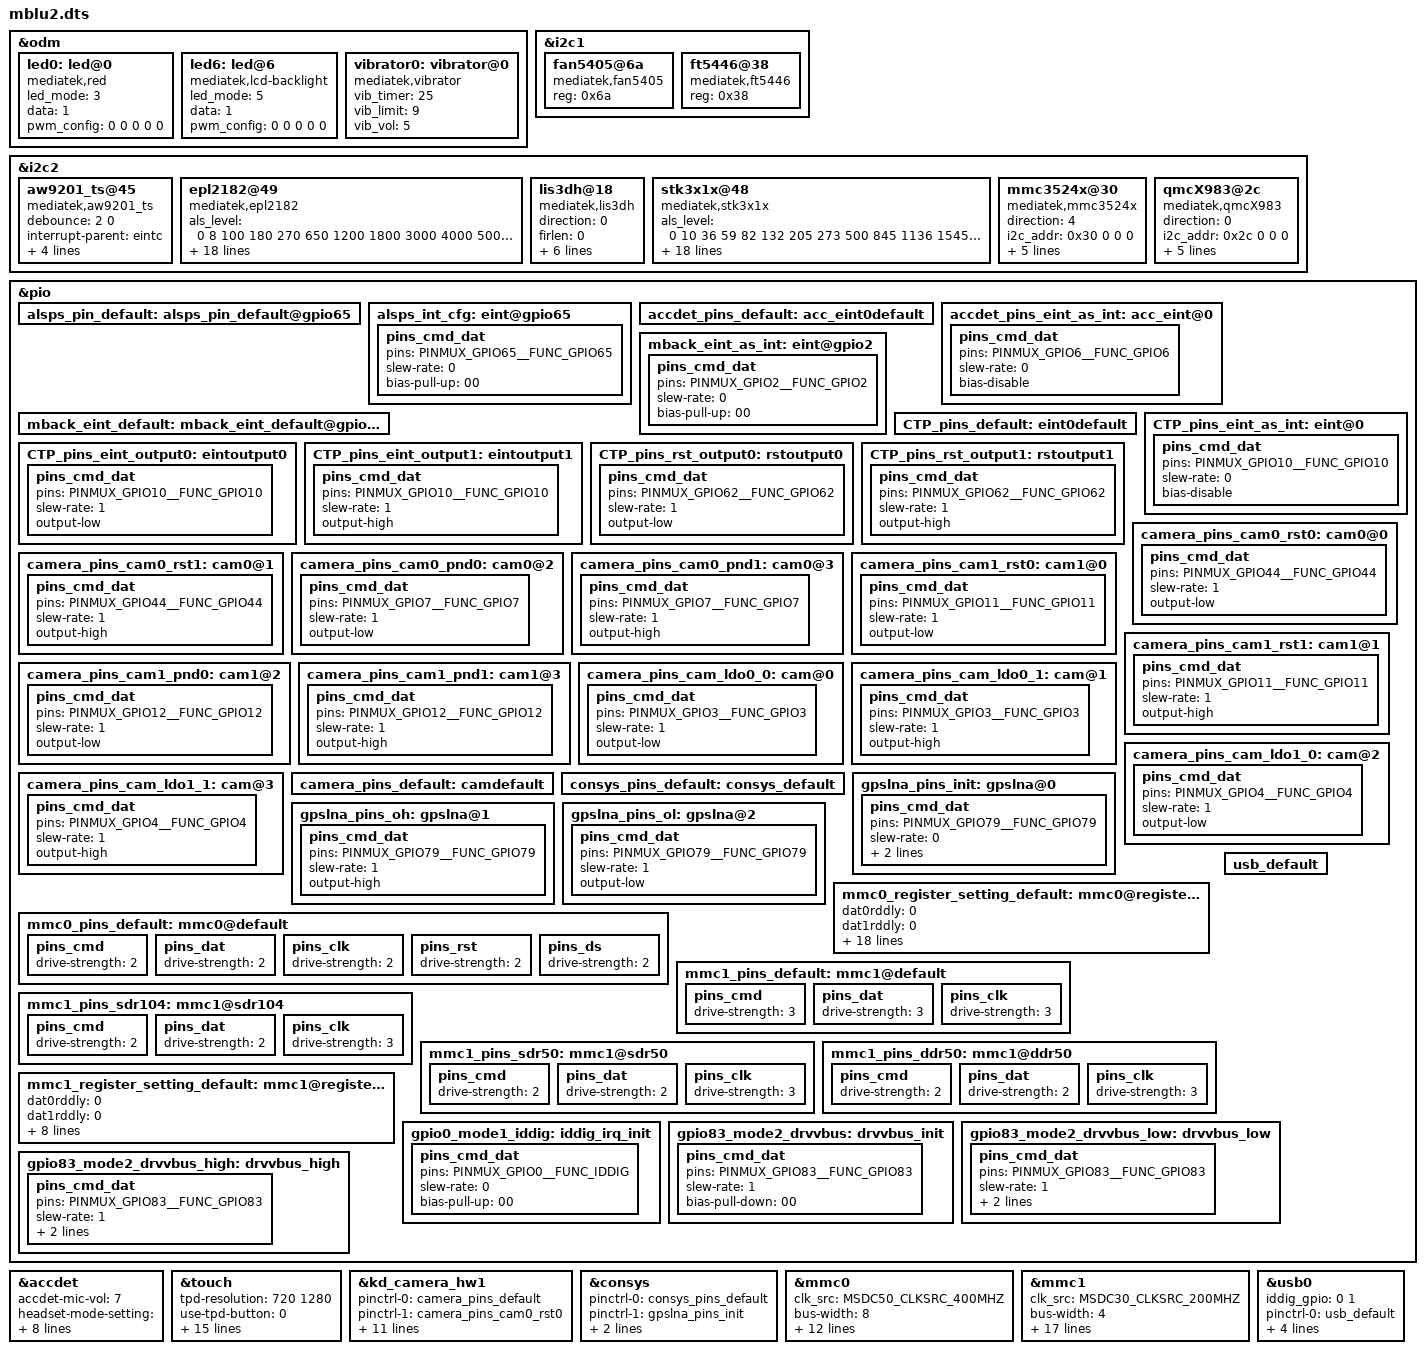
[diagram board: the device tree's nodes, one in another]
#include <generated/autoconf.h>
/dts-v1/;

#include "mt6735.dts"

&odm {
	led0:led@0 {
		compatible = "mediatek,red";
		led_mode = <3>;
		data = <1>;
		pwm_config = <0 0 0 0 0>;
	};

	led6:led@6 {
		compatible = "mediatek,lcd-backlight";
		led_mode = <5>;
		data = <1>;
		pwm_config = <0 0 0 0 0>;
	};

	vibrator0:vibrator@0 {
		compatible = "mediatek,vibrator";
		vib_timer = <25>;
		vib_limit = <9>;
		vib_vol= <5>;
	};
};

&i2c1 {
	fan5405@6a {
		compatible = "mediatek,fan5405";
		reg = <0x6a>;
	};

	ft5446@38 {
		compatible = "mediatek,ft5446";
		reg = <0x38>;
	};
};

&i2c2 {
	aw9201_ts@45 {
		compatible = "mediatek,aw9201_ts";
		debounce = <2 0>;
		interrupt-parent = <&eintc>;
		interrupts = <2 IRQ_TYPE_LEVEL_LOW>;
		pinctrl-0 = <&mback_eint_default>;
		pinctrl-1 = <&mback_eint_as_int>;
		pinctrl-names = "mback_eint_default", "mback_eint_as_int";
		reg = <0x45>;
	};

	epl2182@49 {
		als_level = <0 8 100 180 270 650 1200 1800 3000 4000 5000 7000 9000 15000 20000>;
		als_value = <0 0 150 340 430 570 700 800 950 1500 3000 5000 7000 9000 10240 10240>;
		compatible = "mediatek,epl2182";
		debounce = <65 0>;
		i2c_addr = <0x49 0 0 0>;
		i2c_num = <2>;
		interrupt-parent = <&eintc>;
		interrupts = <65 IRQ_TYPE_LEVEL_LOW>;
		is_batch_supported_als = <0>;
		is_batch_supported_ps = <0>;
		pinctrl-0 = <&alsps_pin_default>;
		pinctrl-1 = <&alsps_int_cfg>;
		pinctrl-names = "pin_default", "pin_cfg";
		polling_mode_als = <1>;
		polling_mode_ps = <0>;
		power_id = <0xffff>;
		power_vol = <0>;
		ps_threshold_high = <610>;
		ps_threshold_low = <466>;
		reg = <0x49>;
	};

	lis3dh@18 {
		compatible = "mediatek,lis3dh";
		direction = <0>;
		firlen = <0>;
		i2c_addr = <0x18 0 0 0>;
		i2c_num = <2>;
		is_batch_supported = <0>;
		power_id = <0xffff>;
		power_vol = <0>;
		reg = <0x18>;
	};

	stk3x1x@48 {
		als_level = <0 10 36 59 82 132 205 273 500 845 1136 1545 2364 4655 6982>;
		als_value = <0 0 150 340 430 570 700 800 950 1500 3000 5000 7000 9000 10240 10240>;
		compatible = "mediatek,stk3x1x";
		debounce = <65 0>;
		i2c_addr = <0x48 0 0 0>;
		i2c_num = <2>;
		interrupt-parent = <&eintc>;
		interrupts = <65 IRQ_TYPE_LEVEL_LOW>;
		is_batch_supported_als = <0>;
		is_batch_supported_ps = <0>;
		pinctrl-0 = <&alsps_pin_default>;
		pinctrl-1 = <&alsps_int_cfg>;
		pinctrl-names = "pin_default", "pin_cfg";
		polling_mode_als = <1>;
		polling_mode_ps = <0>;
		power_id = <0xffff>;
		power_vol = <0>;
		ps_threshold_high = <1700>;
		ps_threshold_low = <1600>;
		reg = <0x48>;
	};

	mmc3524x@30 {
		compatible = "mediatek,mmc3524x";
		direction = <4>;
		i2c_addr = <0x30 0 0 0>;
		i2c_num = <2>;
		is_batch_supported = <0>;
		power_id = <0xffff>;
		power_vol = <0>;
		reg = <0x30>;
	};

	qmcX983@2c {
		compatible = "mediatek,qmcX983";
		direction = <0>;
		i2c_addr = <0x2c 0 0 0>;
		i2c_num = <2>;
		is_batch_supported = <0>;
		power_id = <0xffff>;
		power_vol = <0>;
		reg = <0x2c>;
	};
};

&pio {
	alsps_pin_default: alsps_pin_default@gpio65 {};

	alsps_int_cfg: eint@gpio65 {
		pins_cmd_dat {
			pins = <PINMUX_GPIO65__FUNC_GPIO65>;
			slew-rate = <0>;
			bias-pull-up = <00>;
		};
	};
};

&accdet {
	accdet-mic-vol = <7>;
	headset-mode-setting = <0x500 0x500 1 0x1F0 0x800 0x800 0x20>;
	accdet-plugout-debounce = <20>;
	/* 1:ACC mode, 2:low cost without in bias, 6:low cost with in bias */
	accdet-mic-mode = <1>;
	/* 0--MD_MAX--UP_MAX--DW_MAX */
	headset-three-key-threshold = <0 80 180 500>;
	headset-three-key-threshold-CDD = <0 178 283 600>;
	/* 0--MD_MAX--VOICE_MAX--UP_MAX--DW_MAX */
	headset-four-key-threshold = <0 58 121 192 450>;

	pinctrl-names = "default", "state_eint_as_int";
	pinctrl-0 = <&accdet_pins_default>;
	pinctrl-1 = <&accdet_pins_eint_as_int>;
};

&pio {
	accdet_pins_default: acc_eint0default {};

	accdet_pins_eint_as_int: acc_eint@0 {
		pins_cmd_dat {
			pins = <PINMUX_GPIO6__FUNC_GPIO6>;
			slew-rate = <0>;
			bias-disable;
		};
	};
};

&pio {
	mback_eint_default: mback_eint_default@gpio02 {};

	mback_eint_as_int: eint@gpio2 {
		pins_cmd_dat {
			pins = <PINMUX_GPIO2__FUNC_GPIO2>;
			slew-rate = <0>;
			bias-pull-up = <00>;
		};
	};
};

&touch {
	tpd-resolution = <720 1280>;
	use-tpd-button = <0>;
	tpd-key-num = <0>;
	tpd-key-local= <>;
	tpd-key-dim-local = <0>;
	tpd-max-touch-num = <10>;
	tpd-filter-enable = <1>;
	tpd-filter-pixel-density = <320>;
	tpd-filter-custom-prameters = <0 0 0 0 0 0 0 0 0 0 0 0>;
	tpd-filter-custom-speed = <0 0 0>;
	pinctrl-names = "default", "state_eint_as_int", "state_eint_output0", "state_eint_output1",
			"state_rst_output0", "state_rst_output1";
	pinctrl-0 = <&CTP_pins_default>;
	pinctrl-1 = <&CTP_pins_eint_as_int>;
	pinctrl-2 = <&CTP_pins_eint_output0>;
	pinctrl-3 = <&CTP_pins_eint_output1>;
	pinctrl-4 = <&CTP_pins_rst_output0>;
	pinctrl-5 = <&CTP_pins_rst_output1>;
};

&pio {
	CTP_pins_default: eint0default {};

	CTP_pins_eint_as_int: eint@0 {
		pins_cmd_dat {
			pins = <PINMUX_GPIO10__FUNC_GPIO10>;
			slew-rate = <0>;
			bias-disable;
		};
	};

	CTP_pins_eint_output0: eintoutput0 {
		pins_cmd_dat {
			pins = <PINMUX_GPIO10__FUNC_GPIO10>;
			slew-rate = <1>;
			output-low;
		};
	};

	CTP_pins_eint_output1: eintoutput1 {
		pins_cmd_dat {
			pins = <PINMUX_GPIO10__FUNC_GPIO10>;
			slew-rate = <1>;
			output-high;
		};
	};

	CTP_pins_rst_output0: rstoutput0 {
		pins_cmd_dat {
			pins = <PINMUX_GPIO62__FUNC_GPIO62>;
			slew-rate = <1>;
			output-low;
		};
	};

	CTP_pins_rst_output1: rstoutput1 {
		pins_cmd_dat {
			pins = <PINMUX_GPIO62__FUNC_GPIO62>;
			slew-rate = <1>;
			output-high;
		};
	};
};

&pio {
	camera_pins_cam0_rst0: cam0@0 {
		pins_cmd_dat {
			pins = <PINMUX_GPIO44__FUNC_GPIO44>; /* GPIO_CAMERA_CMRST_PIN */
			slew-rate = <1>; /* direction 0:in, 1:out */
			output-low; /* direction out used only. output_low or high */
		};
	};

	camera_pins_cam0_rst1: cam0@1 {
		pins_cmd_dat {
			pins = <PINMUX_GPIO44__FUNC_GPIO44>; /* GPIO_CAMERA_CMRST_PIN */
			slew-rate = <1>;
			output-high;
		};
	};

	camera_pins_cam0_pnd0: cam0@2 {
		pins_cmd_dat {
			pins = <PINMUX_GPIO7__FUNC_GPIO7>; /* GPIO_CAMERA_CMPDN_PIN */
			slew-rate = <1>;
			output-low;
		};
	};

	camera_pins_cam0_pnd1: cam0@3 {
		pins_cmd_dat {
			pins = <PINMUX_GPIO7__FUNC_GPIO7>; /* GPIO_CAMERA_CMPDN_PIN */
			slew-rate = <1>;
			output-high;
		};
	};

	camera_pins_cam1_rst0: cam1@0 {
		pins_cmd_dat {
			pins = <PINMUX_GPIO11__FUNC_GPIO11>; /* GPIO_CAMERA_CMRST1_PIN */
			slew-rate = <1>; /*direction 0:in, 1:out */
			output-low; /* direction out used only. output_low or high */
		};
	};

	camera_pins_cam1_rst1: cam1@1 {
		pins_cmd_dat {
			pins = <PINMUX_GPIO11__FUNC_GPIO11>; /* GPIO_CAMERA_CMRST1_PIN */
			slew-rate = <1>;
			output-high;
		};
	};

	camera_pins_cam1_pnd0: cam1@2 {
		pins_cmd_dat {
			pins = <PINMUX_GPIO12__FUNC_GPIO12>; /* GPIO_CAMERA_CMPDN1_PIN */
			slew-rate = <1>;
			output-low;
		};
	};

	camera_pins_cam1_pnd1: cam1@3 {
		pins_cmd_dat {
			pins = <PINMUX_GPIO12__FUNC_GPIO12>; /* GPIO_CAMERA_CMPDN1_PIN */
			slew-rate = <1>;
			output-high;
		};
	};

	camera_pins_cam_ldo0_0: cam@0 {
		pins_cmd_dat {
			pins = <PINMUX_GPIO3__FUNC_GPIO3>;
			slew-rate = <1>;
			output-low;
		};
	};

	camera_pins_cam_ldo0_1: cam@1 {
		pins_cmd_dat {
			pins = <PINMUX_GPIO3__FUNC_GPIO3>;
			slew-rate = <1>;
			output-high;
		};
	};
	camera_pins_cam_ldo1_0: cam@2 {
		pins_cmd_dat {
			pins = <PINMUX_GPIO4__FUNC_GPIO4>;
			slew-rate = <1>;
			output-low;
		};
	};
	camera_pins_cam_ldo1_1: cam@3 {
		pins_cmd_dat {
			pins = <PINMUX_GPIO4__FUNC_GPIO4>;
			slew-rate = <1>;
			output-high;
		};
	};

	camera_pins_default: camdefault {};
};

&kd_camera_hw1 {
	pinctrl-names = "default", "cam0_rst0", "cam0_rst1", "cam0_pnd0", "cam0_pnd1",
			"cam1_rst0", "cam1_rst1", "cam1_pnd0", "cam1_pnd1",
			"cam_ldo0_0", "cam_ldo0_1", "cam_ldo1_0", "cam_ldo1_1";
	pinctrl-0 = <&camera_pins_default>;
	pinctrl-1 = <&camera_pins_cam0_rst0>;
	pinctrl-2 = <&camera_pins_cam0_rst1>;
	pinctrl-3 = <&camera_pins_cam0_pnd0>;
	pinctrl-4 = <&camera_pins_cam0_pnd1>;
	pinctrl-5 = <&camera_pins_cam1_rst0>;
	pinctrl-6 = <&camera_pins_cam1_rst1>;
	pinctrl-7 = <&camera_pins_cam1_pnd0>;
	pinctrl-8 = <&camera_pins_cam1_pnd1>;
	pinctrl-9 = <&camera_pins_cam_ldo0_0>;
	pinctrl-10 = <&camera_pins_cam_ldo0_1>;
	pinctrl-11 = <&camera_pins_cam_ldo1_0>;
	pinctrl-12 = <&camera_pins_cam_ldo1_1>;
};

&pio {
	consys_pins_default: consys_default {};

	gpslna_pins_init: gpslna@0 {
		pins_cmd_dat {
			pins = <PINMUX_GPIO79__FUNC_GPIO79>;
			slew-rate = <0>;
			bias-disable;
			output-low;
		};
	};

	gpslna_pins_oh: gpslna@1 {
		pins_cmd_dat {
			pins = <PINMUX_GPIO79__FUNC_GPIO79>;
			slew-rate = <1>;
			output-high;
		};
	};

	gpslna_pins_ol: gpslna@2 {
		pins_cmd_dat {
			pins = <PINMUX_GPIO79__FUNC_GPIO79>;
			slew-rate = <1>;
			output-low;
		};
	};
};

&consys {
	pinctrl-names = "default", "gps_lna_state_init", "gps_lna_state_oh", "gps_lna_state_ol";
	pinctrl-0 = <&consys_pins_default>;
	pinctrl-1 = <&gpslna_pins_init>;
	pinctrl-2 = <&gpslna_pins_oh>;
	pinctrl-3 = <&gpslna_pins_ol>;
};

&mmc0 {
	clk_src = /bits/ 8 <MSDC50_CLKSRC_400MHZ>;
	bus-width = <8>;
	max-frequency = <200000000>;
	cap-mmc-highspeed;
	msdc-sys-suspend;
	mmc-ddr-1_8v;
	mmc-hs200-1_8v;
	mmc-hs400-1_8v;
	non-removable;
	pinctl = <&mmc0_pins_default>;
	register_setting = <&mmc0_register_setting_default>;
	host_function = /bits/ 8 <MSDC_EMMC>;
	bootable;
	status = "okay";
};

&mmc1 {
	clk_src = /bits/ 8 <MSDC30_CLKSRC_200MHZ>;
	bus-width = <4>;
	max-frequency = <200000000>;
	msdc-sys-suspend;
	cap-sd-highspeed;
	sd-uhs-sdr12;
	sd-uhs-sdr25;
	sd-uhs-sdr50;
	sd-uhs-sdr104;
	sd-uhs-ddr50;
	pinctl = <&mmc1_pins_default>;
	pinctl_sdr104 = <&mmc1_pins_sdr104>;
	pinctl_sdr50 = <&mmc1_pins_sdr50>;
	pinctl_ddr50 = <&mmc1_pins_ddr50>;
	register_setting = <&mmc1_register_setting_default>;
	host_function = /bits/ 8 <MSDC_SD>;
	cd_level = /bits/ 8 <MSDC_CD_HIGH>;
	cd-gpios = <&pio 5 0>;
	status = "okay";
};

&pio {
	mmc0_pins_default: mmc0@default {
		pins_cmd {
			drive-strength = /bits/ 8 <2>;
		};

		pins_dat {
			drive-strength = /bits/ 8 <2>;
		};

		pins_clk {
			drive-strength = /bits/ 8 <2>;
		};

		pins_rst {
			drive-strength = /bits/ 8 <2>;
		};

		pins_ds {
			drive-strength = /bits/ 8 <2>;
		};
	};

	mmc0_register_setting_default: mmc0@register_default {
		dat0rddly = /bits/ 8 <0>;
		dat1rddly = /bits/ 8 <0>;
		dat2rddly = /bits/ 8 <0>;
		dat3rddly = /bits/ 8 <0>;
		dat4rddly = /bits/ 8 <0>;
		dat5rddly = /bits/ 8 <0>;
		dat6rddly = /bits/ 8 <0>;
		dat7rddly = /bits/ 8 <0>;
		datwrddly = /bits/ 8 <0>;
		cmdrrddly = /bits/ 8 <0>;
		cmdrddly = /bits/ 8 <0>;
		cmd_edge = /bits/ 8 <MSDC_SMPL_FALLING>;
		rdata_edge = /bits/ 8 <MSDC_SMPL_FALLING>;
		wdata_edge = /bits/ 8 <MSDC_SMPL_FALLING>;

		ett-hs200-cells = <12>;
		ett-hs200-default = <OFFSET_MSDC_PATCH_BIT0	MSDC_PB0_INT_DAT_LATCH_CK_SEL 0x0
				     OFFSET_MSDC_PATCH_BIT0	MSDC_PB0_CKGEN_MSDC_DLY_SEL   0x0
				     OFFSET_MSDC_PATCH_BIT1	MSDC_PB1_CMD_RSP_TA_CNTR      0x1
				     OFFSET_MSDC_IOCON		MSDC_IOCON_RSPL               0x0
				     OFFSET_MSDC_PAD_TUNE0	MSDC_PAD_TUNE0_CMDRDLY        0x7
				     OFFSET_MSDC_PAD_TUNE0	MSDC_PAD_TUNE0_CMDRRDLY       0xb
				     OFFSET_MSDC_PATCH_BIT1	MSDC_PB1_WRDAT_CRCS_TA_CNTR   0x1
				     OFFSET_MSDC_PAD_TUNE0	MSDC_PAD_TUNE0_DATWRDLY       0xb
				     OFFSET_MSDC_IOCON		MSDC_IOCON_W_D0SPL            0x0
				     OFFSET_MSDC_DAT_RDDLY0	MSDC_DAT_RDDLY0_D0            0x7
				     OFFSET_MSDC_PAD_TUNE0	MSDC_PAD_TUNE0_DATRRDLY       0x9
				     OFFSET_MSDC_IOCON		MSDC_IOCON_R_D_SMPL           0x0>;

		ett-hs400-cells = <8>;
		ett-hs400-default = <OFFSET_MSDC_PATCH_BIT0	MSDC_PB0_INT_DAT_LATCH_CK_SEL	0x0
				     OFFSET_MSDC_PATCH_BIT0	MSDC_PB0_CKGEN_MSDC_DLY_SEL	0x0
				     OFFSET_EMMC50_PAD_DS_TUNE	MSDC_EMMC50_PAD_DS_TUNE_DLY1	0x2
				     OFFSET_EMMC50_PAD_DS_TUNE	MSDC_EMMC50_PAD_DS_TUNE_DLY3	0x10
				     OFFSET_MSDC_PATCH_BIT1	MSDC_PB1_CMD_RSP_TA_CNTR	0x1
				     OFFSET_MSDC_IOCON		MSDC_IOCON_RSPL			0x0
				     OFFSET_MSDC_PAD_TUNE0	MSDC_PAD_TUNE0_CMDRDLY		0x6
				     OFFSET_MSDC_PAD_TUNE0	MSDC_PAD_TUNE0_CMDRRDLY		0x6>;
	};

	mmc1_pins_default: mmc1@default {
		pins_cmd {
			drive-strength = /bits/ 8 <3>;
		};

		pins_dat {
			drive-strength = /bits/ 8 <3>;
		};

		pins_clk {
			drive-strength = /bits/ 8 <3>;
		};
	};

	mmc1_pins_sdr104: mmc1@sdr104 {
		pins_cmd {
			drive-strength = /bits/ 8 <2>;
		};

		pins_dat {
			drive-strength = /bits/ 8 <2>;
		};

		pins_clk {
			drive-strength = /bits/ 8 <3>;
		};
	};

	mmc1_pins_sdr50: mmc1@sdr50 {
		pins_cmd {
			drive-strength = /bits/ 8 <2>;
		};

		pins_dat {
			drive-strength = /bits/ 8 <2>;
		};

		pins_clk {
			drive-strength = /bits/ 8 <3>;
		};
	};

	mmc1_pins_ddr50: mmc1@ddr50 {
		pins_cmd {
			drive-strength = /bits/ 8 <2>;
		};

		pins_dat {
			drive-strength = /bits/ 8 <2>;
		};

		pins_clk {
			drive-strength = /bits/ 8 <3>;
		};
	};

	mmc1_register_setting_default: mmc1@register_default {
		dat0rddly = /bits/ 8 <0>;
		dat1rddly = /bits/ 8 <0>;
		dat2rddly = /bits/ 8 <0>;
		dat3rddly = /bits/ 8 <0>;
		datwrddly = /bits/ 8 <0>;
		cmdrrddly = /bits/ 8 <0>;
		cmdrddly = /bits/ 8 <0>;
		cmd_edge = /bits/ 8 <MSDC_SMPL_FALLING>;
		rdata_edge = /bits/ 8 <MSDC_SMPL_FALLING>;
		wdata_edge = /bits/ 8 <MSDC_SMPL_FALLING>;
	};
};

&pio {
	usb_default: usb_default {};

	gpio0_mode1_iddig: iddig_irq_init {
		pins_cmd_dat {
			pins = <PINMUX_GPIO0__FUNC_IDDIG>;
			slew-rate = <0>;
			bias-pull-up = <00>;
		};
	};

	gpio83_mode2_drvvbus: drvvbus_init {
		pins_cmd_dat {
			pins = <PINMUX_GPIO83__FUNC_GPIO83>;
			slew-rate = <1>;
			bias-pull-down = <00>;
		};
	};

	gpio83_mode2_drvvbus_low: drvvbus_low {
		pins_cmd_dat {
			pins = <PINMUX_GPIO83__FUNC_GPIO83>;
			slew-rate = <1>;
			output-low;
			bias-pull-down = <00>;
		};
	};

	gpio83_mode2_drvvbus_high: drvvbus_high {
		pins_cmd_dat {
			pins = <PINMUX_GPIO83__FUNC_GPIO83>;
			slew-rate = <1>;
			output-high;
			bias-pull-down = <00>;
		};
	};
};

&usb0 {
	iddig_gpio = <0 1>;
	pinctrl-names = "usb_default", "iddig_irq_init", "drvvbus_init", "drvvbus_low", "drvvbus_high";
	pinctrl-0 = <&usb_default>;
	pinctrl-1 = <&gpio0_mode1_iddig>;
	pinctrl-2 = <&gpio83_mode2_drvvbus>;
	pinctrl-3 = <&gpio83_mode2_drvvbus_low>;
	pinctrl-4 = <&gpio83_mode2_drvvbus_high>;
};

#include <mblu2/cust.dtsi>
